# ESP32-S31 register map
Vendor: ESPRESSIF SYSTEMS (SHANGHAI) CO., LTD.; Series: ESP32 S-Series; File version: 1
CPU: RV32IMAFC r0p0, little endian, no MPU, FPU, 0 interrupt priority bits
Address unit: 32 bits
Registers are 32-bit, read-write, reset 0x0 unless marked. A register's access mark holds for its fields unless they carry their own. Offsets are from the block's base; [hi:lo] are bit positions; {n}, {i} and the like mark numbered series.

## DS — Digital Signature
Base 0x2050C000
{0x0+i} Y_MEM[{i}] (i=0..511) 8-bit access not given — memory that stores Y
{0x200+i} M_MEM[{i}] (i=0..511) 8-bit access not given — memory that stores M
{0x400+i} RB_MEM[{i}] (i=0..511) 8-bit access not given — memory that stores Rb
{0x600+i} BOX_MEM[{i}] (i=0..47) 8-bit access not given — memory that stores BOX
{0x630+i} IV_MEM[{i}] (i=0..15) 8-bit access not given — memory that stores IV
{0x800+i} X_MEM[{i}] (i=0..511) 8-bit access not given — memory that stores X
{0xA00+i} Z_MEM[{i}] (i=0..511) 8-bit access not given — memory that stores Z
0xE00 SET_START wo — Activates the DS module
  [0] SET_START — Configures whether or not to activate the DS peripheral.\\ 0: Invalid\\ 1: Activate the DS peripheral\\
0xE04 SET_CONTINUE wo — DS continue control register
  [0] SET_CONTINUE — set this bit to continue DS operation.
0xE08 SET_FINISH wo — Ends DS operation
  [0] SET_FINISH — Configures whether or not to end DS operation. \\ 0: Invalid\\ 1: End DS operation\\
0xE0C QUERY_BUSY ro — Status of the DS module
  [0] QUERY_BUSY — Represents whether or not the DS module is idle.\\ 0: The DS module is idle\\ 1: The DS module is busy\\
0xE10 QUERY_KEY_WRONG ro — Checks the reason why \begin{math}DS_KEY\end{math} is not ready
  [3:0] QUERY_KEY_WRONG — Represents the specific problem with HMAC initialization.\\ 0: HMAC is not called\\ 1-15: HMAC was activated, but the DS peripheral did not successfully receive the \begin{math}DS_KEY\end{math} from the HMAC peripheral. (The biggest value is 15)\\
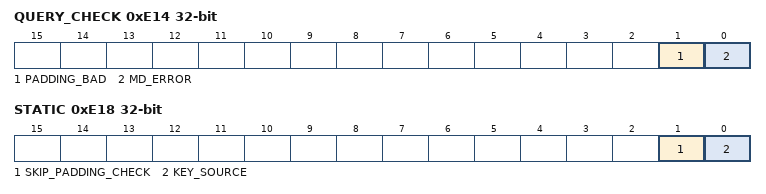
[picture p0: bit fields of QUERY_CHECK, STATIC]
0xE14 QUERY_CHECK ro — Queries DS check result
  [1] PADDING_BAD — Represents whether or not the padding check passes.\\ 0: The padding check passes\\ 1: The padding check fails\\
  [0] MD_ERROR — Represents whether or not the MD check passes.\\ 0: The MD check passes\\ 1: The MD check fails\\
0xE18 STATIC — DS configure key source register
  [1] SKIP_PADDING_CHECK — digital signature padding check bypass bit. \\ 1'b0: padding check enabled.\\ 1'b1: padding check skipped. \\
  [0] KEY_SOURCE — digital signature key source bit. \\ 1'b0: key is from hmac.\\ 1'b1: key is from key manager. \\
0xE20 DATE reset 0x20250819 — DS version control register
  [29:0] DATE — ds version information
0xE24 TIMEOUT_LIMIT reset 0xFFFFFFFF — DS timeout limit configurate register
  [31:0] TIMEOUT_LIMIT — The timeout limitation for waiting sub-IP.

## ECC — ECC (ECC Hardware Accelerator)
Base 0x2050B000
0x0C MULT_INT_RAW ro — ECC raw interrupt status register
  [0] CALC_DONE — The raw interrupt status of the ECC_CALC_DONE_INT interrupt.
0x10 MULT_INT_ST ro — ECC masked interrupt status register
  [0] CALC_DONE — The masked interrupt status of the ECC_CALC_DONE_INT interrupt.
0x14 MULT_INT_ENA — ECC interrupt enable register
  [0] CALC_DONE — Write 1 to enable the ECC_CALC_DONE_INT interrupt.
0x18 MULT_INT_CLR wo — ECC interrupt clear register
  [0] CALC_DONE write-1-clears — Write 1 to clear the ECC_CALC_DONE_INT interrupt.
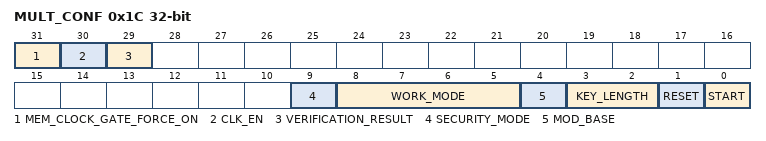
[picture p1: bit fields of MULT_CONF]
0x1C MULT_CONF access per field — ECC configuration register
  [31] MEM_CLOCK_GATE_FORCE_ON rw — Configures whether to force on ECC memory clock gate. \\ 0: No effect\\ 1: Force on\\
  [30] CLK_EN rw — Configures whether to force on register clock gate. \\ 0: No effect\\ 1: Force on\\
  [29] VERIFICATION_RESULT ro — Represents the verification result of ECC Accelerator, valid only when calculation is done.
  [9] SECURITY_MODE rw — Configures the security mode of ECC Accelerator.\\ 0: no secure function enabled.\\ 1: enable constant-time calculation in all point multiplication modes.\\
  [8:5] WORK_MODE rw — Configures the work mode of ECC Accelerator.\\ 0: Point Multi mode\\ 1: Reserved\\ 2: Point Verif mode\\ 3: Point Verif + Multi mode\\ 4: Jacobian Point Multi mode\\ 5: Reserved\\ 6: Jacobian Point Verif mode\\ 7: Point Verif + Jacobian Point Multi mode\\ 8: Mod Add mode\\ 9. Mod Sub mode\\ 10: Mod Multi mode\\ 11: Mod Div mode\\
  [4] MOD_BASE rw — Configures the mod base of mod operation, only valid in work_mode 8-11. \\ 0: n(order of curve)\\ 1: p(mod base of curve)\\
  [3:2] KEY_LENGTH rw — Configures the key length mode bit of ECC Accelerator. \\ 0: P-192\\ 1: P-256\\ 2: P-384\\ 3: SM2.\\
    0=P192 (P-192 elliptic curve); 1=P256 (P-256 elliptic curve); 2=P384 (P-384 elliptic curve)
  [1] RESET wo — Configures whether to reset ECC Accelerator. \\ 0: No effect\\ 1: Reset\\
  [0] START rw — Configures whether to start calculation of ECC Accelerator. This bit will be self-cleared after the calculation is done. \\ 0: No effect\\ 1: Start calculation of ECC Accelerator\\
0x20 MULT_FREE reset 0x1 — ECC free status register
  [0] MULT_FREE — ECC mult free state register \\ 0: non-free \\ 1: free \\
0xFC MULT_DATE reset 0x2506190 — Version control register
  [27:0] MULT_DATE — ECC mult version control register
{0x100+4i} K_MEM{i} (i=0..11) access not given — The memory that stores k.
{0x130+4i} PX_MEM{i} (i=0..11) access not given — The memory that stores Px.
{0x160+4i} PY_MEM{i} (i=0..11) access not given — The memory that stores Py.
{0x190+4i} QX_MEM{i} (i=0..11) access not given — The memory that stores Qx.
{0x1C0+4i} QY_MEM{i} (i=0..11) access not given — The memory that stores Qy.
{0x1F0+4i} QZ_MEM{i} (i=0..11) access not given — The memory that stores Qz.
